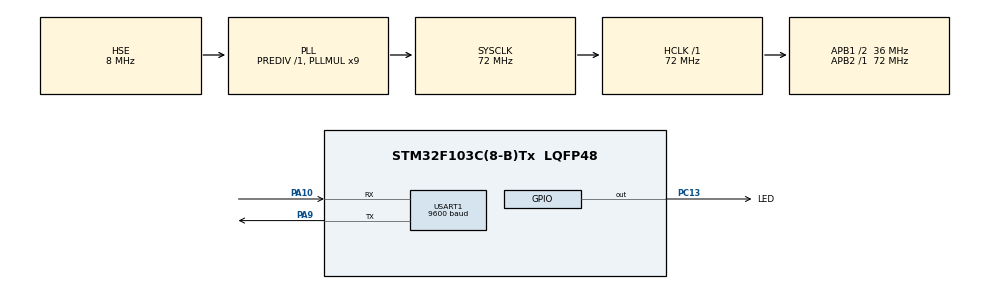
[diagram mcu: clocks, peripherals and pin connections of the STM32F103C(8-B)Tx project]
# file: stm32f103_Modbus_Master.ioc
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FREERTOS.Tasks01=defaultTask,0,128,StartDefaultTask,Default,NULL,Dynamic,NULL,NULL
Mcu.Family=STM32F1
Mcu.Name=STM32F103C(8-B)Tx
Mcu.Package=LQFP48
NVIC.PriorityGroup=NVIC_PRIORITYGROUP_4
NVIC.TIM3_IRQn=true\:5\:0\:false\:false\:true\:true\:true\:true
NVIC.TIM4_IRQn=true\:0\:0\:false\:false\:true\:false\:false\:true
NVIC.TimeBase=TIM4_IRQn
NVIC.TimeBaseIP=TIM4
NVIC.USART1_IRQn=true\:5\:0\:false\:false\:true\:true\:true\:true
PA10.Mode=Asynchronous
PA10.Signal=USART1_RX
PA13.Mode=Trace_Asynchronous_SW
PA13.Signal=SYS_JTMS-SWDIO
PA14.Mode=Trace_Asynchronous_SW
PA14.Signal=SYS_JTCK-SWCLK
PA9.Mode=Asynchronous
PA9.Signal=USART1_TX
PB3.Mode=Trace_Asynchronous_SW
PB3.Signal=SYS_JTDO-TRACESWO
PC13-TAMPER-RTC.GPIO_Label=LED
PC13-TAMPER-RTC.GPIO_PuPd=GPIO_PULLDOWN
PC13-TAMPER-RTC.PinState=GPIO_PIN_SET
PC13-TAMPER-RTC.Signal=GPIO_Output
PC14-OSC32_IN.Mode=LSE-External-Oscillator
PC14-OSC32_IN.Signal=RCC_OSC32_IN
PC15-OSC32_OUT.Mode=LSE-External-Oscillator
PC15-OSC32_OUT.Signal=RCC_OSC32_OUT
PD0-OSC_IN.Mode=HSE-External-Oscillator
PD0-OSC_IN.Signal=RCC_OSC_IN
PD1-OSC_OUT.Mode=HSE-External-Oscillator
PD1-OSC_OUT.Signal=RCC_OSC_OUT
ProjectManager.HeapSize=0x200
ProjectManager.StackSize=0x400
ProjectManager.TargetToolchain=STM32CubeIDE
RCC.AHBFreq_Value=72000000
RCC.APB1CLKDivider=RCC_HCLK_DIV2
RCC.APB1Freq_Value=36000000
RCC.APB1TimFreq_Value=72000000
RCC.APB2Freq_Value=72000000
RCC.APB2TimFreq_Value=72000000
RCC.EnbaleCSS=true
RCC.HCLKFreq_Value=72000000
RCC.PLLMUL=RCC_PLL_MUL9
RCC.PLLSourceVirtual=RCC_PLLSOURCE_HSE
RCC.SYSCLKFreq_VALUE=72000000
RCC.SYSCLKSource=RCC_SYSCLKSOURCE_PLLCLK
RCC.USBFreq_Value=72000000
TIM3.Period=0
TIM3.Prescaler=1800
USART1.BaudRate=9600
USART1.VirtualMode=VM_ASYNC
VP_CRC_VS_CRC.Mode=CRC_Activate
VP_FREERTOS_VS_CMSIS_V1.Mode=CMSIS_V1
VP_SYS_VS_tim4.Mode=TIM4
VP_TIM3_VS_ClockSourceINT.Mode=Internal
board=custom

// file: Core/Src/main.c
/* USER CODE BEGIN Header */
/**
 ******************************************************************************
 * @file           : main.c
 * @brief          : Main program body
 ******************************************************************************
 * @attention
 *
 * <h2><center>&copy; Copyright (c) 2020 STMicroelectronics.
 * All rights reserved.</center></h2>
 *
 * This software component is licensed by ST under Ultimate Liberty license
 * SLA0044, the "License"; You may not use this file except in compliance with
 * the License. You may obtain a copy of the License at:
 *                             www.st.com/SLA0044
 *
 ******************************************************************************
 */
/* USER CODE END Header */

#include "main.h"
#include "cmsis_os.h"
#include "crc.h"
#include "tim.h"
#include "usart.h"
#include "gpio.h"

/* USER CODE BEGIN Includes */
#include "ModbusRTU.h"
/* USER CODE END Includes */

void SystemClock_Config(void);
void MX_FREERTOS_Init(void);

int main(void)
{

  /* MCU Configuration--------------------------------------------------------*/

  /* Reset of all peripherals, Initializes the Flash interface and the Systick. */
  HAL_Init();

  /* Configure the system clock */
  SystemClock_Config();

  /* Initialize all configured peripherals */
  MX_GPIO_Init();
  MX_CRC_Init();
  MX_USART1_UART_Init();
  MX_TIM3_Init();

  /* Call init function for freertos objects (in freertos.c) */
  MX_FREERTOS_Init();
  /* Start scheduler */
  osKernelStart();

  /* We should never get here as control is now taken by the scheduler */
  /* Infinite loop */
  while (1)
  {

  }
}

void SystemClock_Config(void)
{
  RCC_OscInitTypeDef RCC_OscInitStruct = {0};
  RCC_ClkInitTypeDef RCC_ClkInitStruct = {0};

  /** Initializes the CPU, AHB and APB busses clocks
  */
  RCC_OscInitStruct.OscillatorType = RCC_OSCILLATORTYPE_HSE;
  RCC_OscInitStruct.HSEState = RCC_HSE_ON;
  RCC_OscInitStruct.HSEPredivValue = RCC_HSE_PREDIV_DIV1;
  RCC_OscInitStruct.HSIState = RCC_HSI_ON;
  RCC_OscInitStruct.PLL.PLLState = RCC_PLL_ON;
  RCC_OscInitStruct.PLL.PLLSource = RCC_PLLSOURCE_HSE;
  RCC_OscInitStruct.PLL.PLLMUL = RCC_PLL_MUL9;
  if (HAL_RCC_OscConfig(&RCC_OscInitStruct) != HAL_OK)
  {
    Error_Handler();
  }
  /** Initializes the CPU, AHB and APB busses clocks
  */
  RCC_ClkInitStruct.ClockType = RCC_CLOCKTYPE_HCLK|RCC_CLOCKTYPE_SYSCLK
                              |RCC_CLOCKTYPE_PCLK1|RCC_CLOCKTYPE_PCLK2;
  RCC_ClkInitStruct.SYSCLKSource = RCC_SYSCLKSOURCE_PLLCLK;
  RCC_ClkInitStruct.AHBCLKDivider = RCC_SYSCLK_DIV1;
  RCC_ClkInitStruct.APB1CLKDivider = RCC_HCLK_DIV2;
  RCC_ClkInitStruct.APB2CLKDivider = RCC_HCLK_DIV1;

  if (HAL_RCC_ClockConfig(&RCC_ClkInitStruct, FLASH_LATENCY_2) != HAL_OK)
  {
    Error_Handler();
  }
  /** Enables the Clock Security System
  */
  HAL_RCC_EnableCSS();
}

/* USER CODE BEGIN 4 */
void HAL_UART_TxCpltCallback(UART_HandleTypeDef *huart)
{
  if (huart->Instance == USART1)
  {
	HAL_GPIO_TogglePin(LED_GPIO_Port, LED_Pin);
	HAL_TIM_Base_Start_IT(&htim3);
  }
}

/* USER CODE END 4 */

 /**
  * @brief  Period elapsed callback in non blocking mode
  * @note   This function is called  when TIM4 interrupt took place, inside
  * HAL_TIM_IRQHandler(). It makes a direct call to HAL_IncTick() to increment
  * a global variable "uwTick" used as application time base.
  * @param  htim : TIM handle
  * @retval None
  */
void HAL_TIM_PeriodElapsedCallback(TIM_HandleTypeDef *htim)
{
  if (htim->Instance == TIM4) {
    HAL_IncTick();
  }
  /* USER CODE BEGIN Callback 1 */
  if (htim->Instance == TIM3)
  {
  Modbus1.Modbus_Delaytime--;
  if (Modbus1.Modbus_Delaytime--)
  {
    HAL_GPIO_TogglePin(LED_GPIO_Port, LED_Pin);
    Modbus1.Modbus_Status = Modbus_Ready;
  }
  }

  /* USER CODE END Callback 1 */
}

void Error_Handler(void)
{
}

/************************ (C) COPYRIGHT STMicroelectronics *****END OF FILE****/

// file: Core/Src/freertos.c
/* USER CODE BEGIN Header */
/**
 ******************************************************************************
 * File Name          : freertos.c
 * Description        : Code for freertos applications
 ******************************************************************************
 * @attention
 *
 * <h2><center>&copy; Copyright (c) 2020 STMicroelectronics.
 * All rights reserved.</center></h2>
 *
 * This software component is licensed by ST under Ultimate Liberty license
 * SLA0044, the "License"; You may not use this file except in compliance with
 * the License. You may obtain a copy of the License at:
 *                             www.st.com/SLA0044
 *
 ******************************************************************************
 */
/* USER CODE END Header */

#include "FreeRTOS.h"
#include "task.h"
#include "main.h"
#include "cmsis_os.h"

/* USER CODE BEGIN Includes */
#include "usart.h"
/* USER CODE END Includes */

osThreadId defaultTaskHandle;

void StartDefaultTask(void const * argument);

void MX_FREERTOS_Init(void); /* (MISRA C 2004 rule 8.1) */

/* GetIdleTaskMemory prototype (linked to static allocation support) */
void vApplicationGetIdleTaskMemory( StaticTask_t **ppxIdleTaskTCBBuffer, StackType_t **ppxIdleTaskStackBuffer, uint32_t *pulIdleTaskStackSize );

/* USER CODE BEGIN GET_IDLE_TASK_MEMORY */
static StaticTask_t xIdleTaskTCBBuffer;
static StackType_t xIdleStack[configMINIMAL_STACK_SIZE];

void vApplicationGetIdleTaskMemory(StaticTask_t **ppxIdleTaskTCBBuffer,
	StackType_t **ppxIdleTaskStackBuffer, uint32_t *pulIdleTaskStackSize)
{
  *ppxIdleTaskTCBBuffer = &xIdleTaskTCBBuffer;
  *ppxIdleTaskStackBuffer = &xIdleStack[0];
  *pulIdleTaskStackSize = configMINIMAL_STACK_SIZE;
  /* place for user code */
}
/* USER CODE END GET_IDLE_TASK_MEMORY */

void MX_FREERTOS_Init(void) {

  /* Create the thread(s) */
  /* definition and creation of defaultTask */
  osThreadDef(defaultTask, StartDefaultTask, osPriorityNormal, 0, 128);
  defaultTaskHandle = osThreadCreate(osThread(defaultTask), NULL);

}

void StartDefaultTask(void const * argument)
{
  /* USER CODE BEGIN StartDefaultTask */
  //char ch = 'A';
  uint8_t TxMessage[] =
	  "\r\n****UART-Hyperterminal communication based on IT ****\r\n";
  /* Infinite loop */
  for (;;)
  {
	osDelay(3000);
  }
  /* USER CODE END StartDefaultTask */
}

/************************ (C) COPYRIGHT STMicroelectronics *****END OF FILE****/
